# HT32F175x register map
File version: 1.0
Registers are 32-bit, read-write, reset 0x0 unless marked. A register's access mark holds for its fields unless they carry their own. Offsets are from the block's base; [hi:lo] are bit positions; {n}, {i} and the like mark numbered series.

## GPIOA
Base 0x4001A000
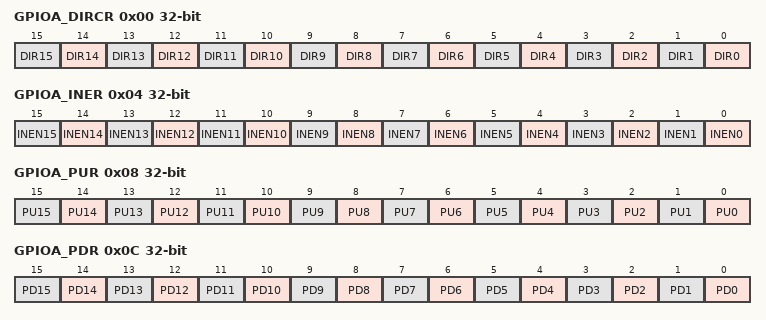
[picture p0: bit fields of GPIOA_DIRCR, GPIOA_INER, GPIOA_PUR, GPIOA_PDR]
0x00 GPIOA_DIRCR
  [n] DIR{n} (n=0..15)
0x04 GPIOA_INER
  [n] INEN{n} (n=0..15)
0x08 GPIOA_PUR
  [n] PU{n} (n=0..15)
0x0C GPIOA_PDR
  [n] PD{n} (n=0..15)
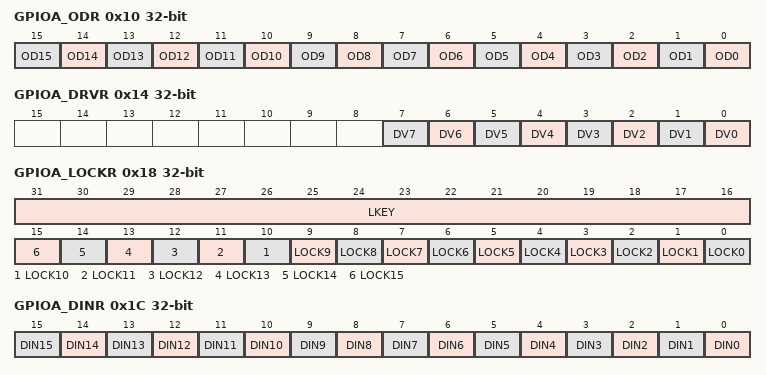
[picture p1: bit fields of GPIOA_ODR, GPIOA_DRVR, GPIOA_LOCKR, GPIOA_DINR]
0x10 GPIOA_ODR
  [n] OD{n} (n=0..15)
0x14 GPIOA_DRVR
  [n] DV{n} (n=0..7)
0x18 GPIOA_LOCKR
  [31:16] LKEY, [n] LOCK{n} (n=0..15)
0x1C GPIOA_DINR
  [n] DIN{n} (n=0..15)
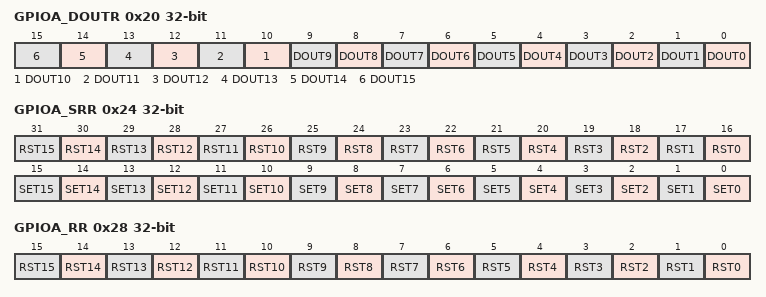
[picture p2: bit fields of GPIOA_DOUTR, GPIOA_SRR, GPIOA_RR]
0x20 GPIOA_DOUTR
  [n] DOUT{n} (n=0..15)
0x24 GPIOA_SRR
  [n+16] RST{n} (n=0..15), [n] SET{n} (n=0..15)
0x28 GPIOA_RR
  [n] RST{n} (n=0..15)

## GPIOB
Base 0x4001B000
Registers as GPIOA (with GPIOA read as GPIOB), without GPIOA_DRVR.

## GPIOC
Base 0x4001C000
Registers as GPIOA (with GPIOA read as GPIOC), without GPIOA_DRVR.

## GPIOD
Base 0x4001D000
Registers as GPIOA (with GPIOA read as GPIOD), without GPIOA_DRVR.

## GPIOE
Base 0x4001E000
Registers as GPIOA (with GPIOA read as GPIOE); these are added or differ:
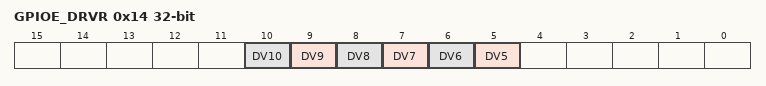
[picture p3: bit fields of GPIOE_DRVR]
0x14 GPIOE_DRVR
  [n] DV{n} (n=5..10)

## AFIO
Base 0x40022000
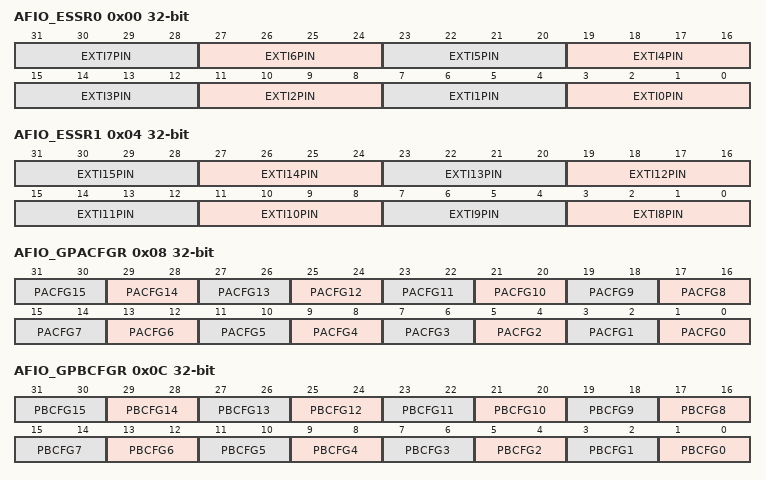
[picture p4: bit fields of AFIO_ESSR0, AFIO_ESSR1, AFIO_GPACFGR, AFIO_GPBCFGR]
0x00 AFIO_ESSR0
  [4n+3:4n] EXTI{n}PIN (n=0..7)
0x04 AFIO_ESSR1
  [4n-29:4n-32] EXTI{n}PIN (n=8..15)
0x08 AFIO_GPACFGR
  [2n+1:2n] PACFG{n} (n=0..15)
0x0C AFIO_GPBCFGR
  [2n+1:2n] PBCFG{n} (n=0..15)
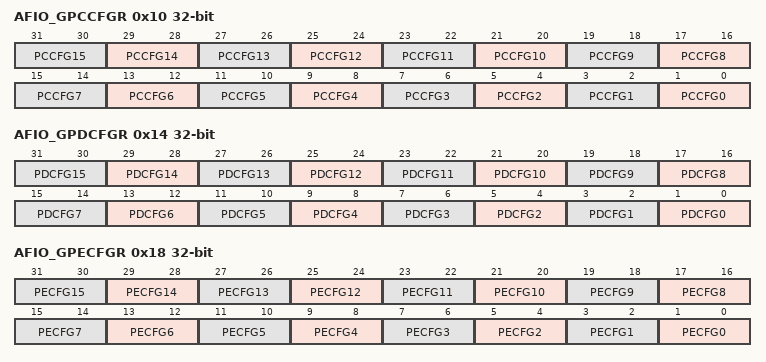
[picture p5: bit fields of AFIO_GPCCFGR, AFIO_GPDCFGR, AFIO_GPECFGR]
0x10 AFIO_GPCCFGR
  [2n+1:2n] PCCFG{n} (n=0..15)
0x14 AFIO_GPDCFGR
  [2n+1:2n] PDCFG{n} (n=0..15)
0x18 AFIO_GPECFGR
  [2n+1:2n] PECFG{n} (n=0..15)

## EXTI
Base 0x40024000
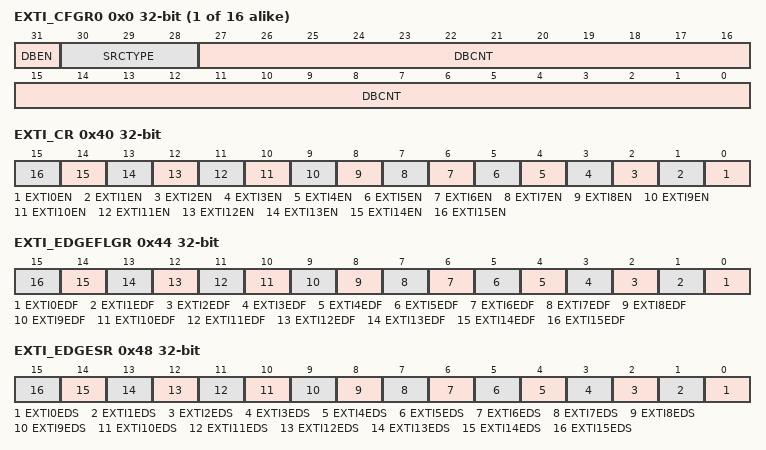
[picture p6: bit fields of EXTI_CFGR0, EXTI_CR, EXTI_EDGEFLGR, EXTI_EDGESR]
{0x0+4i} EXTI_CFGR{i} (i=0..15)
  [31] DBEN, [30:28] SRCTYPE, [27:0] DBCNT
0x40 EXTI_CR
  [n] EXTI{n}EN (n=0..15)
0x44 EXTI_EDGEFLGR
  [n] EXTI{n}EDF (n=0..15)
0x48 EXTI_EDGESR
  [n] EXTI{n}EDS (n=0..15)
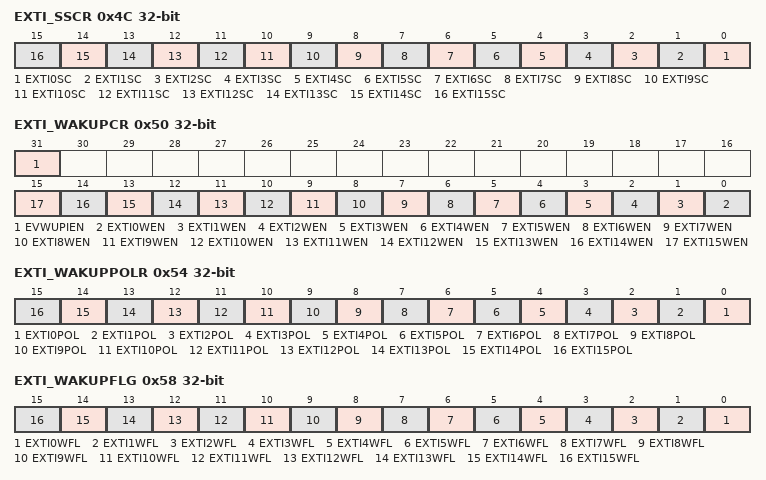
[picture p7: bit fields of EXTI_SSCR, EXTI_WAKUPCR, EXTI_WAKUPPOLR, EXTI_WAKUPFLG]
0x4C EXTI_SSCR
  [n] EXTI{n}SC (n=0..15)
0x50 EXTI_WAKUPCR
  [31] EVWUPIEN, [n] EXTI{n}WEN (n=0..15)
0x54 EXTI_WAKUPPOLR
  [n] EXTI{n}POL (n=0..15)
0x58 EXTI_WAKUPFLG
  [n] EXTI{n}WFL (n=0..15)

## ADC
Base 0x40010000
0x04 ADC_RST
  [0] ADRST
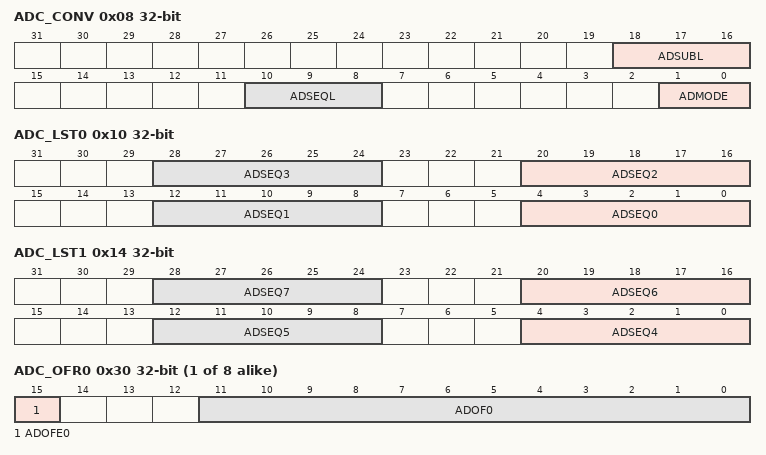
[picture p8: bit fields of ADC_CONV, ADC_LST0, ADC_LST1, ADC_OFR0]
0x08 ADC_CONV
  [18:16] ADSUBL, [10:8] ADSEQL, [1:0] ADMODE
0x10 ADC_LST0
  [8n+4:8n] ADSEQ{n} (n=0..3)
0x14 ADC_LST1
  [8n-28:8n-32] ADSEQ{n} (n=4..7)
{0x30+4i} ADC_OFR{i} (i=0..7)
  [15] ADOFE{i}, [11:0] ADOF{i}
{0x70+4i} ADC_STR{i} (i=0..7)
  [7:0] ADST{i}
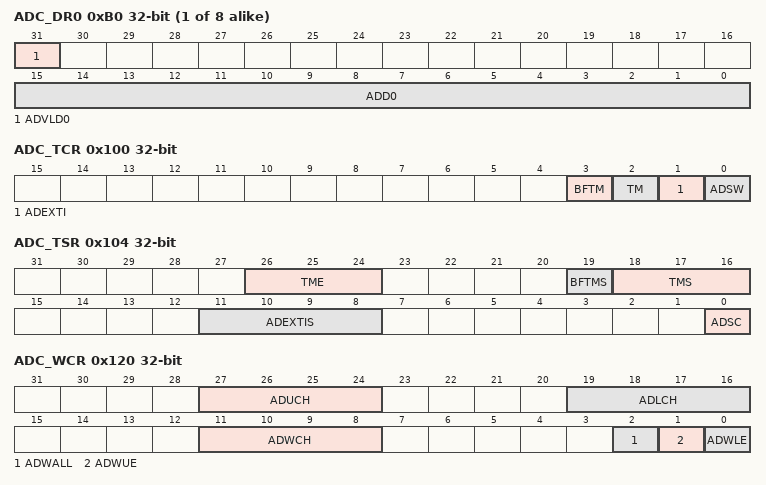
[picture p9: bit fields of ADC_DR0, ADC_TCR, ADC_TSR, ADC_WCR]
{0xB0+4i} ADC_DR{i} (i=0..7)
  [31] ADVLD{i}, [15:0] ADD{i}
0x100 ADC_TCR
  [3] BFTM, [2] TM, [1] ADEXTI, [0] ADSW
0x104 ADC_TSR
  [26:24] TME, [19] BFTMS, [18:16] TMS, [11:8] ADEXTIS, [0] ADSC
0x120 ADC_WCR
  [27:24] ADUCH, [19:16] ADLCH, [11:8] ADWCH, [2] ADWALL, [1] ADWUE, [0] ADWLE
0x124 ADC_LTR
  [11:0] ADLT
0x128 ADC_UTR
  [11:0] ADUT
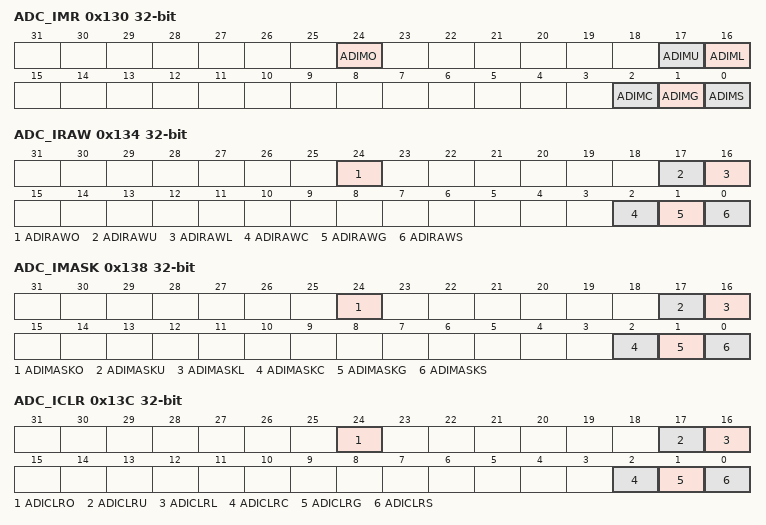
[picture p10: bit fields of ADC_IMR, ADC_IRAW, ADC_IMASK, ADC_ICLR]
0x130 ADC_IMR
  [24] ADIMO, [17] ADIMU, [16] ADIML, [2] ADIMC, [1] ADIMG, [0] ADIMS
0x134 ADC_IRAW
  [24] ADIRAWO, [17] ADIRAWU, [16] ADIRAWL, [2] ADIRAWC, [1] ADIRAWG, [0] ADIRAWS
0x138 ADC_IMASK
  [24] ADIMASKO, [17] ADIMASKU, [16] ADIMASKL, [2] ADIMASKC, [1] ADIMASKG, [0] ADIMASKS
0x13C ADC_ICLR
  [24] ADICLRO, [17] ADICLRU, [16] ADICLRL, [2] ADICLRC, [1] ADICLRG, [0] ADICLRS
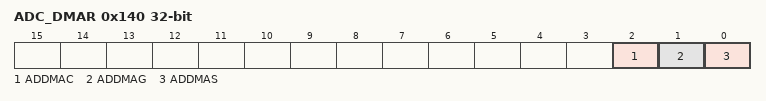
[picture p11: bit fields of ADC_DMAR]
0x140 ADC_DMAR
  [2] ADDMAC, [1] ADDMAG, [0] ADDMAS

## OPACMP
Base 0x40018000
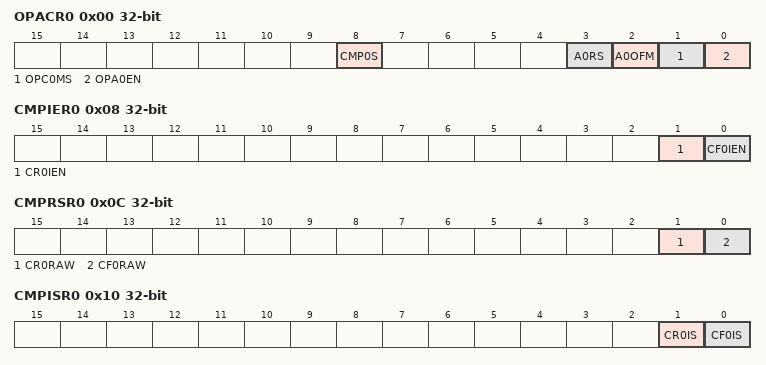
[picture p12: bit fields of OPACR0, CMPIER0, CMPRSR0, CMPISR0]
0x00 OPACR0
  [8] CMP0S, [3] A0RS, [2] A0OFM, [1] OPC0MS, [0] OPA0EN
0x04 OFVCR0
  [5:0] A0OF
0x08 CMPIER0
  [1] CR0IEN, [0] CF0IEN
0x0C CMPRSR0
  [1] CR0RAW, [0] CF0RAW
0x10 CMPISR0
  [1] CR0IS, [0] CF0IS
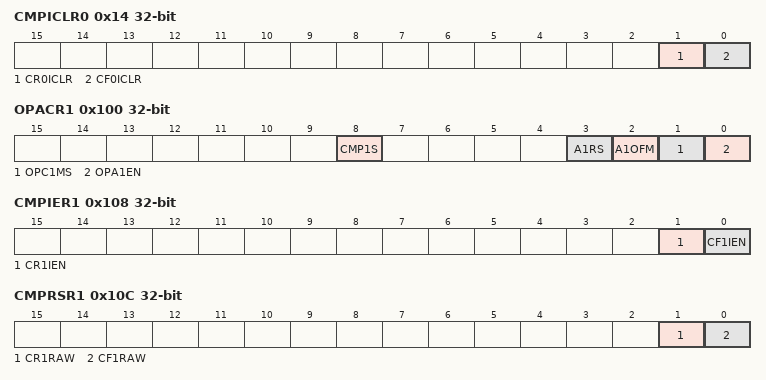
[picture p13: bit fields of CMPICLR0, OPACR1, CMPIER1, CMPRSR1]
0x14 CMPICLR0
  [1] CR0ICLR, [0] CF0ICLR
0x100 OPACR1
  [8] CMP1S, [3] A1RS, [2] A1OFM, [1] OPC1MS, [0] OPA1EN
0x104 OFVCR1
  [5:0] A1OF
0x108 CMPIER1
  [1] CR1IEN, [0] CF1IEN
0x10C CMPRSR1
  [1] CR1RAW, [0] CF1RAW
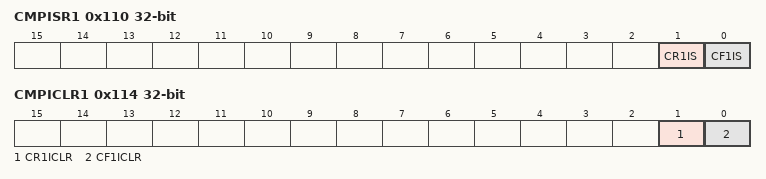
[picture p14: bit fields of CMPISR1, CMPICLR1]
0x110 CMPISR1
  [1] CR1IS, [0] CF1IS
0x114 CMPICLR1
  [1] CR1ICLR, [0] CF1ICLR

## MCTM
Base 0x4002C000
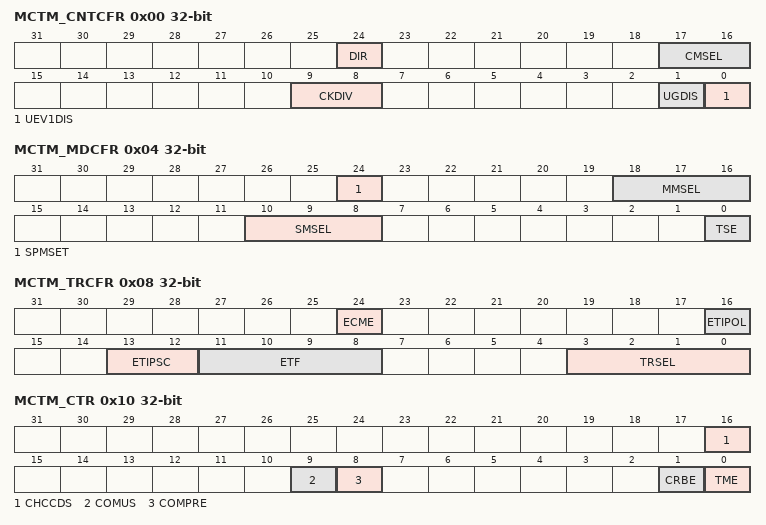
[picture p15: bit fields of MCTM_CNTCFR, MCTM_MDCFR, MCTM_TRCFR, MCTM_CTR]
0x00 MCTM_CNTCFR
  [24] DIR, [17:16] CMSEL, [9:8] CKDIV, [1] UGDIS, [0] UEV1DIS
0x04 MCTM_MDCFR
  [24] SPMSET, [18:16] MMSEL, [10:8] SMSEL, [0] TSE
0x08 MCTM_TRCFR
  [24] ECME, [16] ETIPOL, [13:12] ETIPSC, [11:8] ETF, [3:0] TRSEL
0x10 MCTM_CTR
  [16] CHCCDS, [9] COMUS, [8] COMPRE, [1] CRBE, [0] TME
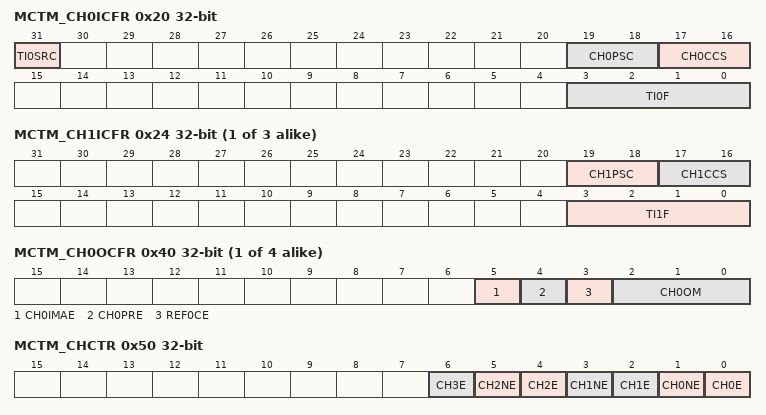
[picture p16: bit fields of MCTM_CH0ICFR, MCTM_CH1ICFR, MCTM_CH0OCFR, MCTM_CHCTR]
0x20 MCTM_CH0ICFR
  [31] TI0SRC, [19:18] CH0PSC, [17:16] CH0CCS, [3:0] TI0F
{0x20+4i} MCTM_CH{i}ICFR (i=1..3)
  [19:18] CH{i}PSC, [17:16] CH{i}CCS, [3:0] TI{i}F
{0x40+4i} MCTM_CH{i}OCFR (i=0..3)
  [5] CH{i}IMAE, [4] CH{i}PRE, [3] REF{i}CE, [2:0] CH{i}OM
0x50 MCTM_CHCTR
  [2n] CH{n}E (n=0..3), [5] CH2NE, [3] CH1NE, [1] CH0NE
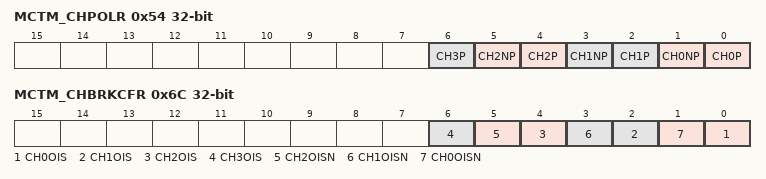
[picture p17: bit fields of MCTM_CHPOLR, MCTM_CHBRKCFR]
0x54 MCTM_CHPOLR
  [2n] CH{n}P (n=0..3), [5] CH2NP, [3] CH1NP, [1] CH0NP
0x6C MCTM_CHBRKCFR
  [2n] CH{n}OIS (n=0..3), [5] CH2OISN, [3] CH1OISN, [1] CH0OISN
0x70 MCTM_CHBRKCTR
  [31:24] CHDTG, [21] CHOSSR, [20] CHOSSI, [17:16] LOCKLV, [11:8] BKF, [5] CHAOE, [4] CHMOE, [1] BKP, [0] BKE
0x74 MCTM_DICTR
  [26] TEVDE, [25] UEV2DE, [24] UEV1DE, [n+16] CH{n}CCDE (n=0..3), [11] BRKIE, [10] TEVIE, [9] UEV2IE, [8] UEV1IE, [n] CH{n}CCIE (n=0..3)
0x78 MCTM_EVGR
  [11] BRKG, [10] TEVG, [9] UEV2G, [8] UEV1G, [n] CH{n}CCG (n=0..3)
0x7C MCTM_INTSR
  [11] BRKIF, [10] TEVIF, [9] UEV2IF, [8] UEV1IF, [n+4] CH{n}OCF (n=0..3), [n] CH{n}CCIF (n=0..3)
0x80 MCTM_CNTR
  [15:0] CNTV
0x84 MCTM_PSCR
  [15:0] PSCV
0x88 MCTM_CRR
  [15:0] CRV
0x8C MCTM_REPR
  [7:0] REPV
{0x90+4i} MCTM_CH{i}CCR (i=0..3)
  [15:0] CH{i}CCV

## GPTM0
Base 0x4006E000
Registers as MCTM (with MCTM read as GPTM0), without MCTM_CHBRKCFR, MCTM_CHBRKCTR, MCTM_REPR; these are added or differ:
0x00 GPTM0_CNTCFR
  [24] DIR, [17:16] CMSEL, [9:8] CKDIV, [1] UGDIS, [0] UEVDIS
0x10 GPTM0_CTR
  [16] CHCCDS, [1] CRBE, [0] TME
0x50 GPTM0_CHCTR
  [2n] CH{n}E (n=0..3)
0x54 GPTM0_CHPOLR
  [2n] CH{n}P (n=0..3)
0x74 GPTM0_DICTR
  [26] TEVDE, [24] UEVDE, [n+16] CH{n}CCDE (n=0..3), [10] TEVIE, [8] UEVIE, [n] CH{n}CCIE (n=0..3)
0x78 GPTM0_EVGR
  [10] TEVG, [8] UEVG, [n] CH{n}CCG (n=0..3)
0x7C GPTM0_INTSR
  [10] TEVIF, [8] UEVIF, [n+4] CH{n}OCF (n=0..3), [n] CH{n}CCIF (n=0..3)

## GPTM1
Base 0x4006F000
Registers as GPTM0 (with GPTM0 read as GPTM1).

## Notices in the file
Copyright (C) 2010 ARM Limited. All rights reserved.
ARM Limited (ARM) is supplying this SVD description for use with Cortex-M3
processor based microcontrollers.  This file and or content can be freely
distributed within development tools that are supporting such ARM based
processors.
THIS SOFTWARE IS PROVIDED "AS IS".  NO WARRANTIES, WHETHER EXPRESS, IMPLIED
OR STATUTORY, INCLUDING, BUT NOT LIMITED TO, IMPLIED WARRANTIES OF
MERCHANTABILITY AND FITNESS FOR A PARTICULAR PURPOSE APPLY TO THIS SOFTWARE.
ARM SHALL NOT, IN ANY CIRCUMSTANCES, BE LIABLE FOR SPECIAL, INCIDENTAL, OR
CONSEQUENTIAL DAMAGES, FOR ANY REASON WHATSOEVER.
